# LargeDummyDevice register map
File version: 1.0
Registers are 32-bit, read-write, no defined reset value unless marked. A register's access mark holds for its fields unless they carry their own. Offsets are from the block's base; [hi:lo] are bit positions.

## PERIPHERAL_28
Base 0x4001B000
0x04 REG_1 — Register 1
  [30:26] FIELD_19, [28:25] FIELD_3, [28:25] FIELD_18, [24:21] FIELD_9, [23:21] FIELD_14, [24:20] FIELD_12, [18:17] FIELD_6, [20:17] FIELD_7, [19:17] FIELD_13, [19:17] FIELD_17, [16] FIELD_11, [12:10] FIELD_1, [14:10] FIELD_4, [10] FIELD_16, [12:9] FIELD_8, [7:6] FIELD_10, [5] FIELD_5, [4:1] FIELD_15, [4:0] FIELD_2
0x08 REG_2 — Register 2
  [31:27] FIELD_2, [23:20] FIELD_5, [19:18] FIELD_3, [18:15] FIELD_1, [15:12] FIELD_4
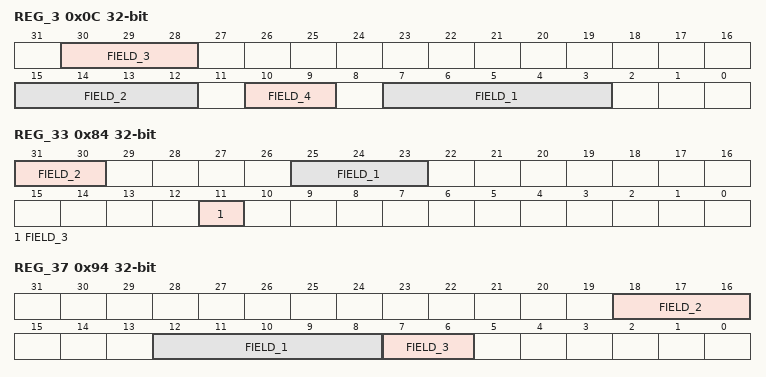
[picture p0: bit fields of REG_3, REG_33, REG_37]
0x0C REG_3 — Register 3
  [30:28] FIELD_3, [15:12] FIELD_2, [10:9] FIELD_4, [7:3] FIELD_1
0x10 REG_4 — Register 4
  [29] FIELD_2, [31:29] FIELD_4, [32:29] FIELD_13, [29] FIELD_22, [31:28] FIELD_21, [29:27] FIELD_24, [29:26] FIELD_23, [27:25] FIELD_28, [27:24] FIELD_8, [24] FIELD_19, [23:22] FIELD_27, [23:20] FIELD_18, [20:19] FIELD_3, [20:17] FIELD_11, [17:16] FIELD_10, [18:15] FIELD_5, [16:15] FIELD_12, [18:14] FIELD_6, [11:9] FIELD_15, [7] FIELD_9, [7:5] FIELD_14, [5:4] FIELD_16, [8:4] FIELD_26, [2:1] FIELD_17, [4:0] FIELD_1, [1:0] FIELD_7, [4:0] FIELD_20, [0] FIELD_25
0x14 REG_5 — Register 5
  [21:20] FIELD_1, [23:20] FIELD_4, [18:17] FIELD_6, [14:11] FIELD_2, [10] FIELD_8, [11:9] FIELD_10, [10:8] FIELD_5, [5] FIELD_3, [6:4] FIELD_11, [4:3] FIELD_9, [6:2] FIELD_7
0x18 REG_6 — Register 6
  [32:29] FIELD_19, [29:28] FIELD_23, [31:28] FIELD_28, [28:27] FIELD_6, [30:26] FIELD_9, [27:26] FIELD_13, [27:25] FIELD_1, [27:24] FIELD_3, [27:24] FIELD_11, [25:24] FIELD_24, [26:23] FIELD_8, [27:23] FIELD_29, [25:23] FIELD_30, [22:19] FIELD_7, [19] FIELD_18, [20:17] FIELD_25, [18:15] FIELD_12, [19:15] FIELD_21, [14] FIELD_14, [12] FIELD_22, [13:10] FIELD_16, [13:9] FIELD_17, [9] FIELD_26, [10:8] FIELD_10, [11:8] FIELD_27, [11:7] FIELD_4, [5:3] FIELD_15, [6:3] FIELD_31, [4:2] FIELD_2, [1] FIELD_5, [2:1] FIELD_20
0x1C REG_7 — Register 7
  [33:31] FIELD_2, [27:24] FIELD_3, [16:15] FIELD_1
0x20 REG_8 — Register 8
  [34:31] FIELD_5, [34:30] FIELD_7, [28] FIELD_1, [27:25] FIELD_4, [20] FIELD_8, [14] FIELD_3, [7:5] FIELD_6, [1] FIELD_2
0x24 REG_9 — Register 9
  [33:31] FIELD_9, [30] FIELD_3, [32:29] FIELD_2, [30:29] FIELD_15, [32:29] FIELD_21, [29] FIELD_24, [27:26] FIELD_1, [30:26] FIELD_28, [25:24] FIELD_14, [23] FIELD_26, [25:22] FIELD_30, [21] FIELD_7, [22:20] FIELD_29, [23:20] FIELD_32, [20:18] FIELD_13, [20:18] FIELD_16, [21:18] FIELD_18, [18] FIELD_20, [17:16] FIELD_8, [16] FIELD_31, [19:15] FIELD_12, [15:14] FIELD_10, [14:13] FIELD_6, [12:11] FIELD_19, [14:10] FIELD_22, [13:9] FIELD_4, [11:9] FIELD_5, [13:9] FIELD_17, [10:9] FIELD_23, [7:6] FIELD_25, [4] FIELD_27, [3:0] FIELD_11
0x28 REG_10 — Register 10
  [35:31] FIELD_6, [31:28] FIELD_10, [31:27] FIELD_11, [29:27] FIELD_25, [29:26] FIELD_22, [26:25] FIELD_4, [26:25] FIELD_16, [28:25] FIELD_19, [25:24] FIELD_17, [24:23] FIELD_2, [20] FIELD_24, [23:19] FIELD_14, [23:19] FIELD_15, [22:18] FIELD_9, [18] FIELD_20, [20:17] FIELD_13, [20:16] FIELD_1, [14:13] FIELD_7, [14:12] FIELD_8, [13:12] FIELD_21, [13:11] FIELD_18, [11] FIELD_23, [11:10] FIELD_26, [13:9] FIELD_3, [13:9] FIELD_12, [10:7] FIELD_5
0x2C REG_11 — Register 11
  [35:31] FIELD_1, [29] FIELD_3, [29:27] FIELD_5, [18] FIELD_8, [19:15] FIELD_6, [13:9] FIELD_7, [7] FIELD_9, [7:3] FIELD_4, [5:2] FIELD_2
0x30 REG_12 — Register 12
  [34:31] FIELD_22, [28:27] FIELD_8, [28:27] FIELD_17, [28:27] FIELD_25, [28:25] FIELD_1, [24] FIELD_7, [27:23] FIELD_2, [22] FIELD_9, [23:21] FIELD_13, [18] FIELD_23, [18:16] FIELD_5, [15] FIELD_11, [17:14] FIELD_15, [16:14] FIELD_16, [15:14] FIELD_18, [14:13] FIELD_10, [15:12] FIELD_4, [13:11] FIELD_24, [12:9] FIELD_14, [11:8] FIELD_3, [8:7] FIELD_20, [8:5] FIELD_6, [7:4] FIELD_12, [6:2] FIELD_19, [2:1] FIELD_21
0x34 REG_13 — Register 13
  [30:29] FIELD_3, [30:28] FIELD_10, [27:26] FIELD_14, [29:25] FIELD_4, [25:21] FIELD_2, [20] FIELD_6, [13] FIELD_16, [12] FIELD_7, [12] FIELD_11, [11:9] FIELD_15, [10:8] FIELD_5, [10:6] FIELD_9, [5] FIELD_1, [5:3] FIELD_13, [6:2] FIELD_8, [5:2] FIELD_12
0x38 REG_14 — Register 14
  [30:29] FIELD_14, [31:27] FIELD_2, [29:27] FIELD_12, [26] FIELD_3, [28:24] FIELD_10, [26:23] FIELD_15, [23:22] FIELD_8, [22:19] FIELD_6, [22:18] FIELD_1, [14:10] FIELD_13, [13:9] FIELD_4, [9] FIELD_9, [9:5] FIELD_16, [3:2] FIELD_5, [3:1] FIELD_11, [0] FIELD_7
0x3C REG_15 — Register 15
  [30] FIELD_5, [32:30] FIELD_14, [29:28] FIELD_11, [28:27] FIELD_6, [29:26] FIELD_3, [26:25] FIELD_10, [26:24] FIELD_12, [25:24] FIELD_15, [27:23] FIELD_9, [25:23] FIELD_18, [23:22] FIELD_2, [23:22] FIELD_16, [20:16] FIELD_8, [14:12] FIELD_17, [10:7] FIELD_7, [10:7] FIELD_13, [5:3] FIELD_1, [4:2] FIELD_4
0x40 REG_16 — Register 16
  [32:30] FIELD_3, [25:23] FIELD_1, [21] FIELD_8, [17:16] FIELD_2, [18:15] FIELD_6, [14] FIELD_7, [10:7] FIELD_5, [2] FIELD_4
0x44 REG_17 — Register 17
  [32:31] FIELD_27, [30] FIELD_12, [33:29] FIELD_32, [25] FIELD_8, [29:25] FIELD_9, [26:24] FIELD_31, [23:20] FIELD_17, [21:18] FIELD_23, [16] FIELD_4, [19:16] FIELD_6, [16:14] FIELD_7, [14] FIELD_28, [17:13] FIELD_22, [16:12] FIELD_25, [12:11] FIELD_5, [10] FIELD_13, [9] FIELD_11, [9] FIELD_19, [10:9] FIELD_24, [10:8] FIELD_15, [9:8] FIELD_18, [7] FIELD_1, [8:7] FIELD_10, [10:6] FIELD_3, [9:6] FIELD_16, [7:6] FIELD_21, [3] FIELD_2, [3:2] FIELD_30, [4:1] FIELD_20, [5:1] FIELD_26, [1] FIELD_29, [0] FIELD_14
0x48 REG_18 — Register 18
  [34:30] FIELD_21, [29] FIELD_3, [29] FIELD_8, [33:29] FIELD_22, [29:27] FIELD_9, [27:25] FIELD_1, [26:25] FIELD_12, [29:25] FIELD_15, [24:22] FIELD_19, [19:16] FIELD_18, [15] FIELD_7, [15:11] FIELD_11, [11:10] FIELD_6, [10:7] FIELD_2, [9:6] FIELD_4, [5:4] FIELD_17, [5:1] FIELD_5, [1] FIELD_10, [4:1] FIELD_13, [4:1] FIELD_20, [3:0] FIELD_14, [3:0] FIELD_16
0x4C REG_19 — Register 19
  [22:19] FIELD_2, [21:17] FIELD_7, [15] FIELD_5, [10:7] FIELD_6, [8:7] FIELD_8, [10:6] FIELD_1, [2] FIELD_4, [0] FIELD_3
0x50 REG_20 — Register 20
  [29:26] FIELD_7, [22] FIELD_8, [20:19] FIELD_10, [19:17] FIELD_2, [20:17] FIELD_5, [12:10] FIELD_1, [13:10] FIELD_9, [8] FIELD_6, [6:4] FIELD_3, [6:3] FIELD_11, [2:1] FIELD_4
0x54 REG_21 — Register 21
  [28:26] FIELD_9, [26] FIELD_18, [28:26] FIELD_23, [28:25] FIELD_8, [27:24] FIELD_2, [27:24] FIELD_13, [25:24] FIELD_22, [27:23] FIELD_5, [27:23] FIELD_11, [26:22] FIELD_7, [26:22] FIELD_17, [20] FIELD_24, [24:20] FIELD_25, [22:19] FIELD_21, [21:18] FIELD_19, [18:17] FIELD_10, [19:16] FIELD_16, [16:14] FIELD_3, [11] FIELD_1, [13:11] FIELD_12, [11:9] FIELD_6, [11:8] FIELD_15, [1] FIELD_20, [4:0] FIELD_4, [0] FIELD_14
0x58 REG_22 — Register 22
  [30] FIELD_13, [27:25] FIELD_3, [26:25] FIELD_4, [27:24] FIELD_1, [27:24] FIELD_10, [26:24] FIELD_14, [25:22] FIELD_16, [21:19] FIELD_11, [20:16] FIELD_17, [14:13] FIELD_6, [15:13] FIELD_9, [11] FIELD_8, [14:11] FIELD_15, [10] FIELD_12, [11:9] FIELD_5, [10:8] FIELD_2, [8:4] FIELD_7
0x5C REG_23 — Register 23
  [29] FIELD_1, [31:29] FIELD_5, [28] FIELD_13, [31:27] FIELD_7, [27] FIELD_16, [29:25] FIELD_19, [25:23] FIELD_22, [24:23] FIELD_28, [23:20] FIELD_11, [18] FIELD_18, [20:18] FIELD_20, [18:17] FIELD_24, [15:14] FIELD_17, [16:13] FIELD_8, [15:13] FIELD_9, [17:13] FIELD_15, [12] FIELD_2, [13:12] FIELD_14, [14:12] FIELD_25, [14:11] FIELD_3, [15:11] FIELD_6, [13:11] FIELD_26, [11:7] FIELD_21, [4:3] FIELD_4, [3] FIELD_29, [3:2] FIELD_10, [4:0] FIELD_12, [4:0] FIELD_23, [4:0] FIELD_27
0x60 REG_24 — Register 24
  [24:22] FIELD_11, [24:20] FIELD_18, [21:19] FIELD_2, [22:19] FIELD_15, [20:18] FIELD_6, [19:15] FIELD_7, [17:15] FIELD_9, [10] FIELD_10, [10:9] FIELD_5, [11:8] FIELD_16, [11:7] FIELD_1, [11:7] FIELD_3, [7:6] FIELD_12, [5] FIELD_4, [8:4] FIELD_13, [3:2] FIELD_8, [2] FIELD_14, [2] FIELD_17
0x64 REG_25 — Register 25
  [10:7] FIELD_1, [10:7] FIELD_2, [5] FIELD_3, [6:2] FIELD_4
0x68 REG_26 — Register 26
  [34:31] FIELD_7, [30:28] FIELD_3, [30:27] FIELD_1, [30:26] FIELD_4, [20:17] FIELD_8, [16:13] FIELD_2, [13:9] FIELD_9, [9:6] FIELD_5, [2:1] FIELD_6
0x6C REG_27 — Register 27
  [32:31] FIELD_3, [28:26] FIELD_6, [22:19] FIELD_9, [17:16] FIELD_4, [18:14] FIELD_7, [17:14] FIELD_11, [17:13] FIELD_5, [16:12] FIELD_2, [15:12] FIELD_8, [14:10] FIELD_1, [10:7] FIELD_10
0x70 REG_28 — Register 28
  [32:28] FIELD_16, [29:27] FIELD_1, [31:27] FIELD_2, [28:25] FIELD_6, [26:25] FIELD_7, [25:24] FIELD_17, [28:24] FIELD_19, [26:23] FIELD_14, [21:19] FIELD_15, [22:18] FIELD_3, [21:17] FIELD_9, [18:17] FIELD_11, [20:17] FIELD_13, [15:14] FIELD_4, [11:9] FIELD_8, [8:6] FIELD_12, [7:5] FIELD_5, [4:2] FIELD_18, [3:1] FIELD_10
0x74 REG_29 — Register 29
  [31:30] FIELD_7, [26:25] FIELD_5, [14] FIELD_4, [16:13] FIELD_6, [10:8] FIELD_2, [8:7] FIELD_1, [0] FIELD_3
0x78 REG_30 — Register 30
  [34:30] FIELD_13, [31:30] FIELD_26, [29] FIELD_5, [28:26] FIELD_9, [26] FIELD_12, [29:26] FIELD_17, [28:25] FIELD_14, [28:24] FIELD_24, [24:22] FIELD_7, [24:21] FIELD_2, [23:19] FIELD_1, [22:19] FIELD_18, [22:18] FIELD_19, [19:17] FIELD_3, [17:15] FIELD_16, [15:14] FIELD_21, [12:9] FIELD_15, [10:6] FIELD_25, [2] FIELD_6, [5:2] FIELD_23, [1] FIELD_10, [4:1] FIELD_11, [0] FIELD_4, [2:0] FIELD_8, [1:0] FIELD_20, [2:0] FIELD_22
0x7C REG_31 — Register 31
  [28] FIELD_15, [23] FIELD_5, [23:22] FIELD_9, [23:21] FIELD_6, [19:17] FIELD_3, [19:15] FIELD_2, [13:11] FIELD_1, [11:10] FIELD_4, [10:8] FIELD_8, [6:5] FIELD_11, [3] FIELD_10, [4:3] FIELD_12, [4:3] FIELD_13, [6:2] FIELD_7, [2:1] FIELD_14
0x80 REG_32 — Register 32
  [30] FIELD_4, [30:28] FIELD_1, [24] FIELD_5, [26:23] FIELD_2, [17] FIELD_6, [17:16] FIELD_7, [15:11] FIELD_3
0x84 REG_33 — Register 33
  [31:30] FIELD_2, [25:23] FIELD_1, [11] FIELD_3
0x88 REG_34 — Register 34
  [23] FIELD_2, [22:20] FIELD_1, [19] FIELD_7, [19:17] FIELD_6, [16] FIELD_4, [20:16] FIELD_5, [13] FIELD_3
0x8C REG_35 — Register 35
  [30:29] FIELD_7, [23:22] FIELD_8, [21:18] FIELD_5, [18:17] FIELD_12, [17:16] FIELD_10, [16:14] FIELD_4, [14:11] FIELD_1, [13:11] FIELD_6, [13:11] FIELD_11, [11:7] FIELD_9, [6:5] FIELD_3, [5:3] FIELD_2
0x90 REG_36 — Register 36
  [22] FIELD_3, [22:19] FIELD_7, [21:18] FIELD_4, [16:14] FIELD_8, [18:14] FIELD_12, [16:13] FIELD_11, [14:11] FIELD_10, [11:9] FIELD_6, [11:8] FIELD_1, [5] FIELD_9, [4:3] FIELD_2, [4:2] FIELD_5
0x94 REG_37 — Register 37
  [18:16] FIELD_2, [12:8] FIELD_1, [7:6] FIELD_3
0x98 REG_38 — Register 38
  [33:31] FIELD_1, [31] FIELD_8, [31:29] FIELD_3, [28] FIELD_9, [28:26] FIELD_4, [26] FIELD_5, [24:20] FIELD_11, [20:18] FIELD_6, [8:6] FIELD_2, [4:3] FIELD_7, [3:1] FIELD_10
0x9C REG_39 — Register 39
  [35:31] FIELD_2, [35:31] FIELD_3, [35:31] FIELD_9, [34:31] FIELD_11, [34:31] FIELD_14, [35:31] FIELD_15, [30:29] FIELD_26, [30:28] FIELD_6, [31:28] FIELD_7, [30:28] FIELD_24, [22:19] FIELD_23, [19] FIELD_25, [19] FIELD_27, [20:18] FIELD_10, [18:16] FIELD_22, [15] FIELD_19, [16:14] FIELD_4, [17:14] FIELD_17, [14:13] FIELD_13, [11:9] FIELD_1, [11:8] FIELD_28, [10:7] FIELD_12, [8:7] FIELD_16, [9:5] FIELD_20, [6:5] FIELD_21, [6:3] FIELD_8, [1:0] FIELD_5, [2:0] FIELD_18
0xA0 REG_40 — Register 40
  [27:26] FIELD_2, [28:25] FIELD_1, [26:25] FIELD_3, [25:24] FIELD_7, [24:22] FIELD_4, [20:19] FIELD_5, [21:18] FIELD_18, [19:16] FIELD_17, [14] FIELD_16, [14:13] FIELD_11, [13] FIELD_19, [12] FIELD_6, [11:10] FIELD_10, [12:10] FIELD_14, [11:9] FIELD_9, [8:7] FIELD_12, [8:5] FIELD_13, [7:4] FIELD_20, [7:3] FIELD_8, [0] FIELD_15
0xA4 REG_41 — Register 41
  [29:28] FIELD_1, [23] FIELD_5, [18] FIELD_2, [21:18] FIELD_3, [8:4] FIELD_4
